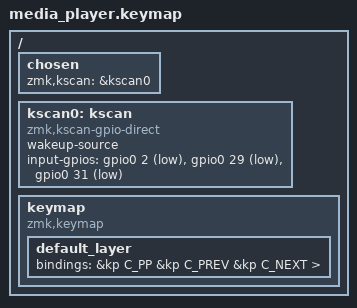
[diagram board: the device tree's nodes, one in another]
#include <behaviors.dtsi>
#include <dt-bindings/zmk/keys.h>

/ {
    chosen {
        zmk,kscan = &kscan0;
    };

    kscan0: kscan {
        compatible = "zmk,kscan-gpio-direct";
        wakeup-source;
        
        input-gpios
            = <&gpio0 2 (GPIO_ACTIVE_LOW | GPIO_PULL_UP)>
            , <&gpio0 29 (GPIO_ACTIVE_LOW | GPIO_PULL_UP)>
            , <&gpio0 31 (GPIO_ACTIVE_LOW | GPIO_PULL_UP)>
            ;
    };

    keymap {
        compatible = "zmk,keymap";

        default_layer {
            bindings = 
                &kp C_PP    &kp C_PREV    &kp C_NEXT
            >;
        };
    };
};
